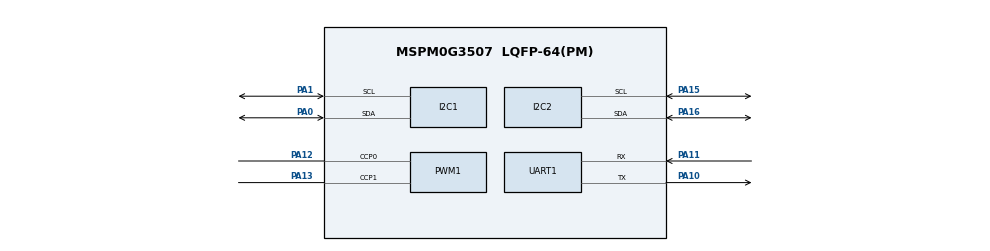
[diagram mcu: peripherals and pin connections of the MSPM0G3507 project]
/**
 * These arguments were used when this file was generated. They will be automatically applied on subsequent loads
 * via the GUI or CLI. Run CLI with '--help' for additional information on how to override these arguments.
 * @cliArgs --device "MSPM0G350X" --part "Default" --package "LQFP-64(PM)" --product "mspm0_sdk@2.10.00.04"
 * @v2CliArgs --device "MSPM0G3507" --package "LQFP-64(PM)" --product "mspm0_sdk@2.10.00.04"
 * @versions {"tool":"1.27.1+4634"}
 */

/**
 * Import the modules used in this configuration.
 */
const GPIO   = scripting.addModule("/ti/driverlib/GPIO", {}, false);
const GPIO1  = GPIO.addInstance();
const GPIO2  = GPIO.addInstance();
const GPIO3  = GPIO.addInstance();
const GPIO4  = GPIO.addInstance();
const GPIO5  = GPIO.addInstance();
const GPIO6  = GPIO.addInstance();
const GPIO7  = GPIO.addInstance();
const GPIO8  = GPIO.addInstance();
const GPIO9  = GPIO.addInstance();
const GPIO10 = GPIO.addInstance();
const GPIO11 = GPIO.addInstance();
const GPIO12 = GPIO.addInstance();
const GPIO13 = GPIO.addInstance();
const GPIO14 = GPIO.addInstance();
const GPIO15 = GPIO.addInstance();
const GPIO16 = GPIO.addInstance();
const GPIO17 = GPIO.addInstance();
const I2C    = scripting.addModule("/ti/driverlib/I2C", {}, false);
const I2C1   = I2C.addInstance();
const I2C2   = I2C.addInstance();
const PWM    = scripting.addModule("/ti/driverlib/PWM", {}, false);
const PWM1   = PWM.addInstance();
const SYSCTL = scripting.addModule("/ti/driverlib/SYSCTL");
const TIMER  = scripting.addModule("/ti/driverlib/TIMER", {}, false);
const TIMER1 = TIMER.addInstance();
const UART   = scripting.addModule("/ti/driverlib/UART", {}, false);
const UART1  = UART.addInstance();

/**
 * Write custom configuration values to the imported modules.
 */
GPIO1.$name                              = "TRACK1";
GPIO1.associatedPins[0].$name            = "PIN_TRACK1";
GPIO1.associatedPins[0].direction        = "INPUT";
GPIO1.associatedPins[0].internalResistor = "PULL_UP";
GPIO1.associatedPins[0].assignedPort     = "PORTB";
GPIO1.associatedPins[0].assignedPin      = "2";

const Board = scripting.addModule("/ti/driverlib/Board", {}, false);

GPIO2.$name                              = "TRACK2";
GPIO2.associatedPins[0].$name            = "PIN_TRACK2";
GPIO2.associatedPins[0].direction        = "INPUT";
GPIO2.associatedPins[0].internalResistor = "PULL_UP";
GPIO2.associatedPins[0].assignedPort     = "PORTB";
GPIO2.associatedPins[0].assignedPin      = "3";

GPIO3.$name                              = "TRACK3";
GPIO3.associatedPins[0].$name            = "PIN_TRACK3";
GPIO3.associatedPins[0].direction        = "INPUT";
GPIO3.associatedPins[0].internalResistor = "PULL_UP";
GPIO3.associatedPins[0].assignedPort     = "PORTB";
GPIO3.associatedPins[0].assignedPin      = "4";

GPIO4.$name                              = "TRACK4";
GPIO4.associatedPins[0].$name            = "PIN_TRACK4";
GPIO4.associatedPins[0].direction        = "INPUT";
GPIO4.associatedPins[0].internalResistor = "PULL_UP";
GPIO4.associatedPins[0].assignedPort     = "PORTB";
GPIO4.associatedPins[0].assignedPin      = "5";

GPIO5.$name                              = "TRACK5";
GPIO5.associatedPins[0].$name            = "PIN_TRACK5";
GPIO5.associatedPins[0].direction        = "INPUT";
GPIO5.associatedPins[0].internalResistor = "PULL_UP";
GPIO5.associatedPins[0].assignedPort     = "PORTB";
GPIO5.associatedPins[0].assignedPin      = "6";

GPIO6.$name                              = "TRACK6";
GPIO6.associatedPins[0].$name            = "PIN_TRACK6";
GPIO6.associatedPins[0].direction        = "INPUT";
GPIO6.associatedPins[0].internalResistor = "PULL_UP";
GPIO6.associatedPins[0].assignedPort     = "PORTB";
GPIO6.associatedPins[0].assignedPin      = "7";

GPIO7.$name                              = "TRACK7";
GPIO7.associatedPins[0].$name            = "PIN_TRACK7";
GPIO7.associatedPins[0].direction        = "INPUT";
GPIO7.associatedPins[0].internalResistor = "PULL_UP";
GPIO7.associatedPins[0].assignedPort     = "PORTB";
GPIO7.associatedPins[0].assignedPin      = "8";

GPIO8.$name                              = "TRACK8";
GPIO8.associatedPins[0].$name            = "PIN_TRACK8";
GPIO8.associatedPins[0].direction        = "INPUT";
GPIO8.associatedPins[0].internalResistor = "PULL_UP";
GPIO8.associatedPins[0].assignedPort     = "PORTB";
GPIO8.associatedPins[0].assignedPin      = "9";

GPIO9.$name                          = "AIN1";
GPIO9.associatedPins[0].$name        = "PIN_AIN1";
GPIO9.associatedPins[0].assignedPort = "PORTB";
GPIO9.associatedPins[0].assignedPin  = "13";

GPIO10.$name                          = "AIN2";
GPIO10.associatedPins[0].$name        = "PIN_AIN2";
GPIO10.associatedPins[0].assignedPort = "PORTB";
GPIO10.associatedPins[0].assignedPin  = "14";

GPIO11.$name                          = "BIN1";
GPIO11.associatedPins[0].$name        = "PIN_BIN1";
GPIO11.associatedPins[0].assignedPort = "PORTB";
GPIO11.associatedPins[0].assignedPin  = "15";

GPIO12.$name                          = "BIN2";
GPIO12.associatedPins[0].$name        = "PIN_BIN2";
GPIO12.associatedPins[0].assignedPort = "PORTB";
GPIO12.associatedPins[0].assignedPin  = "16";

GPIO13.$name                              = "ENC_R_A";
GPIO13.associatedPins[0].$name            = "PIN_ENC_R_A";
GPIO13.associatedPins[0].direction        = "INPUT";
GPIO13.associatedPins[0].internalResistor = "PULL_UP";
GPIO13.associatedPins[0].assignedPort     = "PORTA";
GPIO13.associatedPins[0].assignedPin      = "24";

GPIO14.$name                              = "ENC_R_B";
GPIO14.associatedPins[0].$name            = "PIN_ENC_R_B";
GPIO14.associatedPins[0].direction        = "INPUT";
GPIO14.associatedPins[0].internalResistor = "PULL_UP";
GPIO14.associatedPins[0].assignedPort     = "PORTA";
GPIO14.associatedPins[0].assignedPin      = "17";

GPIO15.$name                              = "GPIO_GRP_0";
GPIO15.associatedPins[0].internalResistor = "PULL_UP";
GPIO15.associatedPins[0].assignedPort     = "PORTB";
GPIO15.associatedPins[0].direction        = "INPUT";
GPIO15.associatedPins[0].$name            = "BTN";
GPIO15.associatedPins[0].assignedPin      = "21";

GPIO16.$name                              = "GPIO_GRP_1";
GPIO16.associatedPins[0].$name            = "ENC_L_A";
GPIO16.associatedPins[0].direction        = "INPUT";
GPIO16.associatedPins[0].internalResistor = "PULL_UP";
GPIO16.associatedPins[0].assignedPort     = "PORTB";
GPIO16.associatedPins[0].assignedPin      = "22";

GPIO17.$name                              = "GPIO_GRP_2";
GPIO17.associatedPins[0].$name            = "ENC_L_B";
GPIO17.associatedPins[0].direction        = "INPUT";
GPIO17.associatedPins[0].internalResistor = "PULL_UP";
GPIO17.associatedPins[0].assignedPort     = "PORTB";
GPIO17.associatedPins[0].assignedPin      = "23";

I2C1.$name                           = "I2C_0";
I2C1.basicEnableController           = true;
I2C1.basicControllerStandardBusSpeed = "Fast";
I2C1.peripheral.$assign              = "I2C0";
I2C1.peripheral.sdaPin.$assign       = "PA0";
I2C1.peripheral.sclPin.$assign       = "PA1";
I2C1.sdaPinConfig.$name              = "ti_driverlib_gpio_GPIOPinGeneric2";
I2C1.sclPinConfig.$name              = "ti_driverlib_gpio_GPIOPinGeneric3";

I2C2.$name                             = "I2C_OLED";
I2C2.basicEnableController             = true;
I2C2.basicControllerStandardBusSpeed   = "Fast";
I2C2.peripheral.sdaPin.$assign         = "PA16";
I2C2.peripheral.sclPin.$assign         = "PA15";
I2C2.sdaPinConfig.hideOutputInversion  = scripting.forceWrite(false);
I2C2.sdaPinConfig.onlyInternalResistor = scripting.forceWrite(false);
I2C2.sdaPinConfig.passedPeripheralType = scripting.forceWrite("Digital");
I2C2.sdaPinConfig.$name                = "ti_driverlib_gpio_GPIOPinGeneric4";
I2C2.sclPinConfig.hideOutputInversion  = scripting.forceWrite(false);
I2C2.sclPinConfig.onlyInternalResistor = scripting.forceWrite(false);
I2C2.sclPinConfig.passedPeripheralType = scripting.forceWrite("Digital");
I2C2.sclPinConfig.$name                = "ti_driverlib_gpio_GPIOPinGeneric5";

PWM1.$name                              = "PWM_MOTOR";
PWM1.clockPrescale                      = 125;
PWM1.peripheral.$assign                 = "TIMG0";
PWM1.peripheral.ccp0Pin.$assign         = "PA12";
PWM1.peripheral.ccp1Pin.$assign         = "PA13";
PWM1.PWM_CHANNEL_0.$name                = "ti_driverlib_pwm_PWMTimerCC0";
PWM1.PWM_CHANNEL_0.invert               = true;
PWM1.PWM_CHANNEL_1.$name                = "ti_driverlib_pwm_PWMTimerCC1";
PWM1.PWM_CHANNEL_1.invert               = true;
PWM1.ccp0PinConfig.direction            = scripting.forceWrite("OUTPUT");
PWM1.ccp0PinConfig.hideOutputInversion  = scripting.forceWrite(false);
PWM1.ccp0PinConfig.onlyInternalResistor = scripting.forceWrite(false);
PWM1.ccp0PinConfig.passedPeripheralType = scripting.forceWrite("Digital");
PWM1.ccp0PinConfig.$name                = "ti_driverlib_gpio_GPIOPinGeneric10";
PWM1.ccp1PinConfig.direction            = scripting.forceWrite("OUTPUT");
PWM1.ccp1PinConfig.hideOutputInversion  = scripting.forceWrite(false);
PWM1.ccp1PinConfig.onlyInternalResistor = scripting.forceWrite(false);
PWM1.ccp1PinConfig.passedPeripheralType = scripting.forceWrite("Digital");
PWM1.ccp1PinConfig.$name                = "ti_driverlib_gpio_GPIOPinGeneric11";

SYSCTL.forceDefaultClkConfig = true;

TIMER1.$name              = "TIMER_0";
TIMER1.timerMode          = "PERIODIC";
TIMER1.timerClkDiv        = 8;
TIMER1.timerClkPrescale   = 99;
TIMER1.timerPeriod        = "20 ms";
TIMER1.interrupts         = ["ZERO"];
TIMER1.timerStartTimer    = true;
TIMER1.peripheral.$assign = "TIMG6";

UART1.$name                    = "UART_0";
UART1.enableFIFO               = true;
UART1.rxFifoThreshold          = "DL_UART_RX_FIFO_LEVEL_ONE_ENTRY";
UART1.enableDMARX              = false;
UART1.enableDMATX              = false;
UART1.targetBaudRate           = 115200;
UART1.enableInternalLoopback   = false;
UART1.peripheral.rxPin.$assign = "PA11";
UART1.peripheral.txPin.$assign = "PA10";
UART1.txPinConfig.$name        = "ti_driverlib_gpio_GPIOPinGeneric0";
UART1.rxPinConfig.$name        = "ti_driverlib_gpio_GPIOPinGeneric1";

/**
 * Pinmux solution for unlocked pins/peripherals. This ensures that minor changes to the automatic solver in a future
 * version of the tool will not impact the pinmux you originally saw.  These lines can be completely deleted in order to
 * re-solve from scratch.
 */
GPIO1.associatedPins[0].pin.$suggestSolution  = "PB2";
Board.peripheral.$suggestSolution             = "DEBUGSS";
Board.peripheral.swclkPin.$suggestSolution    = "PA20";
Board.peripheral.swdioPin.$suggestSolution    = "PA19";
GPIO2.associatedPins[0].pin.$suggestSolution  = "PB3";
GPIO3.associatedPins[0].pin.$suggestSolution  = "PB4";
GPIO4.associatedPins[0].pin.$suggestSolution  = "PB5";
GPIO5.associatedPins[0].pin.$suggestSolution  = "PB6";
GPIO6.associatedPins[0].pin.$suggestSolution  = "PB7";
GPIO7.associatedPins[0].pin.$suggestSolution  = "PB8";
GPIO8.associatedPins[0].pin.$suggestSolution  = "PB9";
GPIO9.associatedPins[0].pin.$suggestSolution  = "PB13";
GPIO10.associatedPins[0].pin.$suggestSolution = "PB14";
GPIO11.associatedPins[0].pin.$suggestSolution = "PB15";
GPIO12.associatedPins[0].pin.$suggestSolution = "PB16";
GPIO13.associatedPins[0].pin.$suggestSolution = "PA24";
GPIO14.associatedPins[0].pin.$suggestSolution = "PA17";
GPIO15.associatedPins[0].pin.$suggestSolution = "PB21";
GPIO16.associatedPins[0].pin.$suggestSolution = "PB22";
GPIO17.associatedPins[0].pin.$suggestSolution = "PB23";
I2C2.peripheral.$suggestSolution              = "I2C1";
SYSCTL.peripheral.$suggestSolution            = "SYSCTL";
UART1.peripheral.$suggestSolution             = "UART0";
